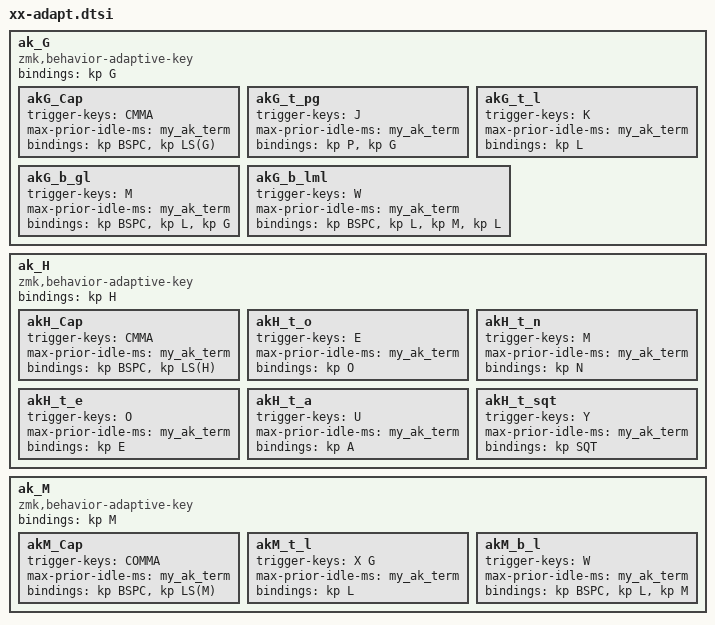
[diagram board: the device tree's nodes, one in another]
/*
 * AdaptiveKey behaviors
 * (send a different behavior based on prior key)
 *
 * very dependant on the underlying alpha layout
 *
 * using urob's behavior-adaptive-key module (https://github.com/urob/zmk-adaptive-key/)
 */
 
        ak_G: ak_G {
            compatible = "zmk,behavior-adaptive-key";
            #binding-cells = <0>;
            bindings = <&kp G>;

            akG_Cap { trigger-keys = <CMMA>; max-prior-idle-ms = <my_ak_term>; bindings = <&kp BSPC &kp LS(G)>; };
            akG_t_pg { trigger-keys = <J>; max-prior-idle-ms = <my_ak_term>; bindings = <&kp P &kp G>; };
            akG_t_l  { trigger-keys = <K>; max-prior-idle-ms = <my_ak_term>; bindings = <&kp L>; };
            akG_b_gl { trigger-keys = <M>; max-prior-idle-ms = <my_ak_term>; bindings = <&kp BSPC &kp L &kp G>; };
            akG_b_lml { trigger-keys = <W>; max-prior-idle-ms = <my_ak_term>; bindings = <&kp BSPC &kp L &kp M &kp L>; };
        };
        ak_H: ak_H {
            compatible = "zmk,behavior-adaptive-key";
            #binding-cells = <0>;
            bindings = <&kp H>;

            akH_Cap { trigger-keys = <CMMA>; max-prior-idle-ms = <my_ak_term>; bindings = <&kp BSPC &kp LS(H)>; };
            akH_t_o { trigger-keys = <E>; max-prior-idle-ms = <my_ak_term>; bindings = <&kp O>; };
            akH_t_n { trigger-keys = <M>; max-prior-idle-ms = <my_ak_term>; bindings = <&kp N>; };
            akH_t_e { trigger-keys = <O>; max-prior-idle-ms = <my_ak_term>; bindings = <&kp E>; };
            akH_t_a { trigger-keys = <U>; max-prior-idle-ms = <my_ak_term>; bindings = <&kp A>; };
            akH_t_sqt { trigger-keys = <Y>; max-prior-idle-ms = <my_ak_term>; bindings = <&kp SQT>; };
        };
        ak_M: ak_M {
            compatible = "zmk,behavior-adaptive-key";
            #binding-cells = <0>;
            bindings = <&kp M>;

            akM_Cap { trigger-keys = <COMMA>; max-prior-idle-ms = <my_ak_term>; bindings = <&kp BSPC &kp LS(M)>; };
            akM_t_l { trigger-keys = <X G>; max-prior-idle-ms = <my_ak_term>; bindings = <&kp L>; };
            akM_b_l { trigger-keys = <W>; max-prior-idle-ms = <my_ak_term>; bindings = <&kp BSPC &kp L &kp M>; };
        };
